# CY8C5868LTI_LP039 register map
File version: 0.1
CY8C58LP
Registers are 8-bit, read-write, no defined reset value unless marked. A register's access mark holds for its fields unless they carry their own. Offsets are from the block's base; lines under a group give offsets from that group; [hi:lo] are bit positions; {n}, {i} and the like mark numbered series; 'fields as' and 'values as' point back to an identical list; <NAME> marks a mode.

## Memory map
0x40004394 USBUART size 0x1D0A — USBFS
0x400049C8 I2C size 0x19

## I2C
Base 0x400049C8
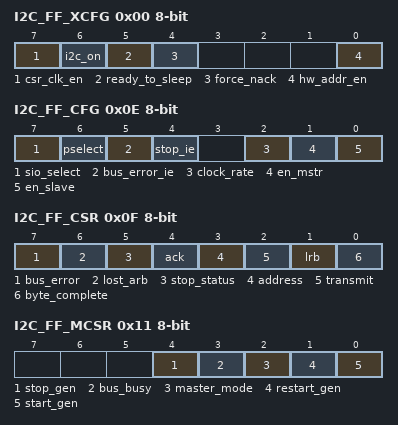
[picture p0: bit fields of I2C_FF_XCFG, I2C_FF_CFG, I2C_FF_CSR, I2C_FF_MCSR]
0x00 I2C_FF_XCFG — Extended Configuration Register: I2C_XCFG
  [7] csr_clk_en, [6] i2c_on, [5] ready_to_sleep ro, [4] force_nack, [0] hw_addr_en
0x02 I2C_FF_ADDR — Slave Adddress Register: I2C_ADR
  [6:0] slave_address — This register holds the slave's 7-bit address.
0x0E I2C_FF_CFG — Configuration Register: I2C_CFG
  [7] sio_select, [6] pselect, [5] bus_error_ie, [4] stop_ie, [2] clock_rate, [1] en_mstr, [0] en_slave
0x0F I2C_FF_CSR — Control and Status Register: I2C_CSR
  [7] bus_error, [6] lost_arb, [5] stop_status, [4] ack, [3] address, [2] transmit, [1] lrb, [0] byte_complete
0x10 I2C_FF_DATA — Data Register: I2C_D
  [7:0] data — This register provides read/write access to the Shift register.
0x11 I2C_FF_MCSR — Master Control and Status Register: I2C_MCSR
  [4] stop_gen, [3] bus_busy ro, [2] master_mode ro, [1] restart_gen, [0] start_gen
0x13 I2C_FF__CLK_DIV1 — Divider of BUS_CLK low part: I2C_CLK_DIV1
  [7:0] Div
0x14 I2C_FF__CLK_DIV2 — Divider high part: I2C_CLK_DIV1
  [1:0] Div
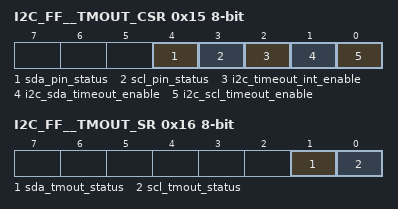
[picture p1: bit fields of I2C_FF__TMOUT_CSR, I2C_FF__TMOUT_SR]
0x15 I2C_FF__TMOUT_CSR — Extended Configuration Register: I2C_TMOUT_CSR
  [4] sda_pin_status, [3] scl_pin_status, [2] i2c_timeout_int_enable ro, [1] i2c_sda_timeout_enable, [0] i2c_scl_timeout_enable
0x16 I2C_FF__TMOUT_SR — Extended Configuration Register: I2C_TMOUT_SR
  [1] sda_tmout_status, [0] scl_tmout_status
0x17 I2C_FF__TMOUT_CFG0 — Extended Configuration Register: TMOUT_CFG0
  [7:0] timeout_period_lowbyte
0x18 I2C_FF__TMOUT_CFG1 — Extended Configuration Register: TMOUT_CFG1
  [3:0] timeout_period_highnibble

## USBUART — USBFS
Base 0x40004394
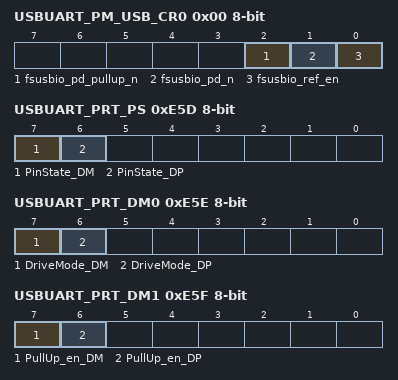
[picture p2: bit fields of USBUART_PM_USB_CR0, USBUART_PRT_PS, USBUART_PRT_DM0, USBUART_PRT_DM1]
0x00 USBUART_PM_USB_CR0 — USB Power Mode Control Register 0
  [2] fsusbio_pd_pullup_n, [1] fsusbio_pd_n, [0] fsusbio_ref_en
0x11 USBUART_PM_ACT_CFG — Active Power Mode Configuration Register
0x21 USBUART_PM_STBY_CFG — Standby Power Mode Configuration Register
0xE5D USBUART_PRT_PS — Port Pin State Register
  [7] PinState_DM ro, [6] PinState_DP ro
0xE5E USBUART_PRT_DM0 — Port Drive Mode Register
  [7] DriveMode_DM, [6] DriveMode_DP
0xE5F USBUART_PRT_DM1 — Port Drive Mode Register
  [7] PullUp_en_DM, [6] PullUp_en_DP
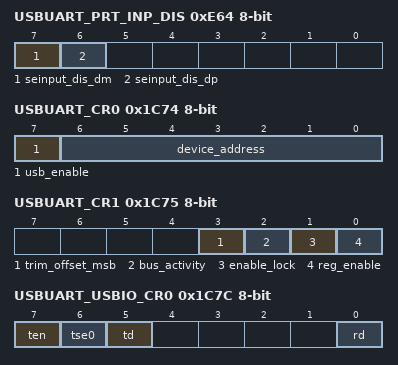
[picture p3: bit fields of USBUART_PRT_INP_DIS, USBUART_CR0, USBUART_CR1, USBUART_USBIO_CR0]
0xE64 USBUART_PRT_INP_DIS — Input buffer disable override
  [7] seinput_dis_dm, [6] seinput_dis_dp
0x1C6C USBUART_EP0_DR0 — bmRequestType
0x1C6D USBUART_EP0_DR1 — bRequest
0x1C6E USBUART_EP0_DR2 — wValueLo
0x1C6F USBUART_EP0_DR3 — wValueHi
0x1C70 USBUART_EP0_DR4 — wIndexLo
0x1C71 USBUART_EP0_DR5 — wIndexHi
0x1C72 USBUART_EP0_DR6 — lengthLo
0x1C73 USBUART_EP0_DR7 — lengthHi
0x1C74 USBUART_CR0 — USB Control Register 0
  [7] usb_enable, [6:0] device_address ro
0x1C75 USBUART_CR1 — USB Control Register 1
  [3] trim_offset_msb, [2] bus_activity, [1] enable_lock, [0] reg_enable
{0x1C6A+0x10*i} USBUART_SIE_EP{i}_CR0 (i=1..8) — The Endpoint{i} Control Register
0x1C7C USBUART_USBIO_CR0 — USBIO Control Register 0
  [7] ten, [6] tse0, [5] td, [0] rd ro
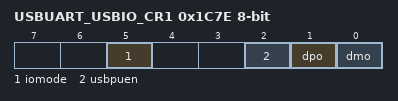
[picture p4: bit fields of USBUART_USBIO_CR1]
0x1C7E USBUART_USBIO_CR1 — USBIO Control Register 1
  [5] iomode, [2] usbpuen, [1] dpo ro, [0] dmo ro
0x1CF8 USBUART_BUF_SIZE — Dedicated Endpoint Buffer Size Register
0x1CFA USBUART_EP_ACTIVE — Endpoint Active Indication Register
0x1CFB USBUART_EP_TYPE — Endpoint Type (IN/OUT) Indication
0x1D09 USBUART_USB_CLK_EN — USB Block Clock Enable Register
